# CTRL_MODULE_CORE_PAD register map
Vendor: Texas Instruments
Registers are 32-bit, access per field, reset 0x10F010F unless marked. A register's access mark holds for its fields unless they carry their own. Offsets are as the file gives them; [hi:lo] are bit positions; {n}, {i} and the like mark numbered series; 'fields as' and 'values as' point back to an identical list.

## CTRL_MODULE_CORE_PAD (part 3 of 7)
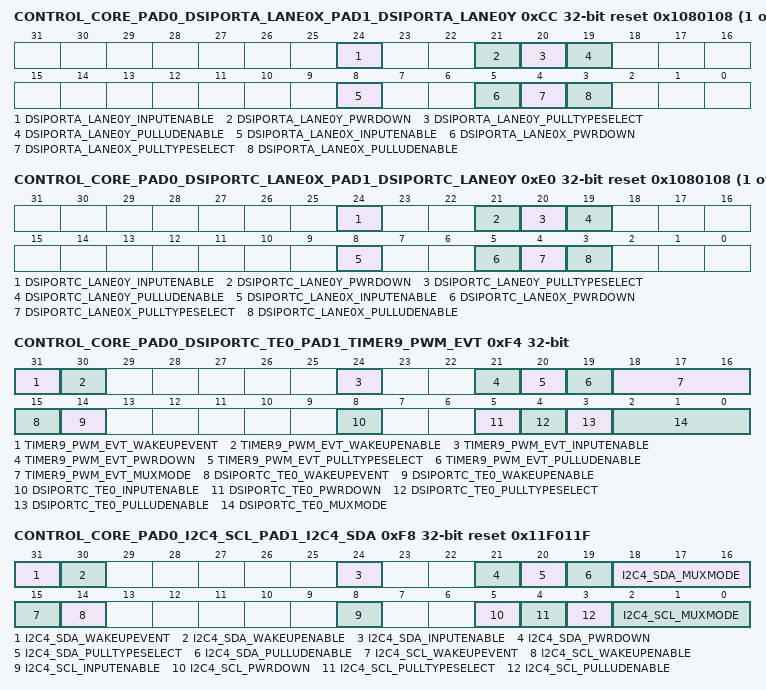
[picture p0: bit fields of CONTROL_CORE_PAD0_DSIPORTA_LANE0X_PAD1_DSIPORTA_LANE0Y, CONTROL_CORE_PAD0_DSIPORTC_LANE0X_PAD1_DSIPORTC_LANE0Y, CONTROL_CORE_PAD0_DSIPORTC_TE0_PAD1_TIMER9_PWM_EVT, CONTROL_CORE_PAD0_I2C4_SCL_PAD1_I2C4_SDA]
{0xCC+4i} CONTROL_CORE_PAD0_DSIPORTA_LANE{i}X_PAD1_DSIPORTA_LANE{i}Y reset 0x1080108 (i=0..4) — Register control for Pads dsiporta_lane{i}x and dsiporta_lane{i}y Access conditions. Read: unrestricted, Write: unrestricted
  [24] DSIPORTA_LANE{i}Y_INPUTENABLE rw — Input enable value for pad dsiporta_lane{i}y
    0=InputBufferDisabled (Input buffer of IO cell is disabled); 1=InputBufferEnabled (Input buffer of IO cell is enabled)
  [21] DSIPORTA_LANE{i}Y_PWRDOWN rw — Power Down setting for pad dsiporta_lane{i}y
    0=PwrDownDisabled (IO cell power is ON); 1=PwrDownEnabled (IO cell power is OFF)
  [20] DSIPORTA_LANE{i}Y_PULLTYPESELECT rw — Pull-Up/Down selection for pad dsiporta_lane{i}y
    0=Pull-Down selected; 1=Pull-Up selected
  [19] DSIPORTA_LANE{i}Y_PULLUDENABLE rw — Pull-Up/Down enable for pad dsiporta_lane{i}y
    0=PullDisabled (Pull-Up/Down disabled); 1=PullEnabled (Pull-Up/Down enabled)
  [8] DSIPORTA_LANE{i}X_INPUTENABLE rw — Input enable value for pad dsiporta_lane{i}x
    values as DSIPORTA_LANE{i}Y_INPUTENABLE
  [5] DSIPORTA_LANE{i}X_PWRDOWN rw — Power Down setting for pad dsiporta_lane{i}x
    values as DSIPORTA_LANE{i}Y_PWRDOWN
  [4] DSIPORTA_LANE{i}X_PULLTYPESELECT rw — Pull-Up/Down selection for pad dsiporta_lane{i}x
    0=Pull-Down selected; 1=Pull-Up selected
  [3] DSIPORTA_LANE{i}X_PULLUDENABLE rw — Pull-Up/Down enable for pad dsiporta_lane{i}x
    values as DSIPORTA_LANE{i}Y_PULLUDENABLE
{0xE0+4i} CONTROL_CORE_PAD0_DSIPORTC_LANE{i}X_PAD1_DSIPORTC_LANE{i}Y reset 0x1080108 (i=0..4) — Register control for Pads dsiportc_lane{i}x and dsiportc_lane{i}y Access conditions. Read: unrestricted, Write: unrestricted
  [24] DSIPORTC_LANE{i}Y_INPUTENABLE rw — Input enable value for pad dsiportc_lane{i}y
    values as CONTROL_CORE_PAD0_DSIPORTA_LANE0X_PAD1_DSIPORTA_LANE0Y.DSIPORTA_LANE{i}Y_INPUTENABLE
  [21] DSIPORTC_LANE{i}Y_PWRDOWN rw — Power Down setting for pad dsiportc_lane{i}y
    values as CONTROL_CORE_PAD0_DSIPORTA_LANE0X_PAD1_DSIPORTA_LANE0Y.DSIPORTA_LANE{i}Y_PWRDOWN
  [20] DSIPORTC_LANE{i}Y_PULLTYPESELECT rw — Pull-Up/Down selection for pad dsiportc_lane{i}y
    0=Pull-Down selected; 1=Pull-Up selected
  [19] DSIPORTC_LANE{i}Y_PULLUDENABLE rw — Pull-Up/Down enable for pad dsiportc_lane{i}y
    values as CONTROL_CORE_PAD0_DSIPORTA_LANE0X_PAD1_DSIPORTA_LANE0Y.DSIPORTA_LANE{i}Y_PULLUDENABLE
  [8] DSIPORTC_LANE{i}X_INPUTENABLE rw — Input enable value for pad dsiportc_lane{i}x
    values as CONTROL_CORE_PAD0_DSIPORTA_LANE0X_PAD1_DSIPORTA_LANE0Y.DSIPORTA_LANE{i}Y_INPUTENABLE
  [5] DSIPORTC_LANE{i}X_PWRDOWN rw — Power Down setting for pad dsiportc_lane{i}x
    values as CONTROL_CORE_PAD0_DSIPORTA_LANE0X_PAD1_DSIPORTA_LANE0Y.DSIPORTA_LANE{i}Y_PWRDOWN
  [4] DSIPORTC_LANE{i}X_PULLTYPESELECT rw — Pull-Up/Down selection for pad dsiportc_lane{i}x
    0=Pull-Down selected; 1=Pull-Up selected
  [3] DSIPORTC_LANE{i}X_PULLUDENABLE rw — Pull-Up/Down enable for pad dsiportc_lane{i}x
    values as CONTROL_CORE_PAD0_DSIPORTA_LANE0X_PAD1_DSIPORTA_LANE0Y.DSIPORTA_LANE{i}Y_PULLUDENABLE
0xF4 CONTROL_CORE_PAD0_DSIPORTC_TE0_PAD1_TIMER9_PWM_EVT — Register control for Pads dsiportc_te0 and timer9_pwm_evt Access conditions. Read: unrestricted, Write: unrestricted
  [31] TIMER9_PWM_EVT_WAKEUPEVENT ro — Pad_x wake-up event status latched in the IO
    1=WakeUp (A wake-up event occurred); 0=No wake-up event occurred
  [30] TIMER9_PWM_EVT_WAKEUPENABLE rw — Input pad wake-up enable
    0=DetectLow (wake-up detection is disabled); 1=DetectLowHigh (wake-up detection is enabled)
  [24] TIMER9_PWM_EVT_INPUTENABLE rw — Input enable value for pad timer9_pwm_evt
    values as CONTROL_CORE_PAD0_DSIPORTA_LANE0X_PAD1_DSIPORTA_LANE0Y.DSIPORTA_LANE{i}Y_INPUTENABLE
  [21] TIMER9_PWM_EVT_PWRDOWN rw — Power Down setting for pad timer9_pwm_evt
    values as CONTROL_CORE_PAD0_DSIPORTA_LANE0X_PAD1_DSIPORTA_LANE0Y.DSIPORTA_LANE{i}Y_PWRDOWN
  [20] TIMER9_PWM_EVT_PULLTYPESELECT rw — Pull-Up/Down selection for pad timer9_pwm_evt
    0=Pull-Down selected; 1=Pull-Up selected
  [19] TIMER9_PWM_EVT_PULLUDENABLE rw — Pull-Up/Down enable for pad timer9_pwm_evt
    values as CONTROL_CORE_PAD0_DSIPORTA_LANE0X_PAD1_DSIPORTA_LANE0Y.DSIPORTA_LANE{i}Y_PULLUDENABLE
  [18:16] TIMER9_PWM_EVT_MUXMODE rw — Functional multiplexing selection for pad timer9_pwm_evt
    0=SEL_TIMER9_PWM_EVT (Select timer9_pwm_evt); 1=SEL_SYNC_SOF_CLK (Select sync_sof_clk); 2=SEL_SYNC_USOF_ITP_CLK (Select sync_usof_itp_clk); 7=SEL_SAFE_MODE_CORE70 (Select safe_mode_core70); 6=SEL_GPIO6_190 (Select gpio6_190)
  [15] DSIPORTC_TE0_WAKEUPEVENT ro — Pad_x wake-up event status latched in the IO
    values as TIMER9_PWM_EVT_WAKEUPEVENT
  [14] DSIPORTC_TE0_WAKEUPENABLE rw — Input pad wake-up enable
    values as TIMER9_PWM_EVT_WAKEUPENABLE
  [8] DSIPORTC_TE0_INPUTENABLE rw — Input enable value for pad dsiportc_te0
    values as CONTROL_CORE_PAD0_DSIPORTA_LANE0X_PAD1_DSIPORTA_LANE0Y.DSIPORTA_LANE{i}Y_INPUTENABLE
  [5] DSIPORTC_TE0_PWRDOWN rw — Power Down setting for pad dsiportc_te0
    values as CONTROL_CORE_PAD0_DSIPORTA_LANE0X_PAD1_DSIPORTA_LANE0Y.DSIPORTA_LANE{i}Y_PWRDOWN
  [4] DSIPORTC_TE0_PULLTYPESELECT rw — Pull-Up/Down selection for pad dsiportc_te0
    0=Pull-Down selected; 1=Pull-Up selected
  [3] DSIPORTC_TE0_PULLUDENABLE rw — Pull-Up/Down enable for pad dsiportc_te0
    values as CONTROL_CORE_PAD0_DSIPORTA_LANE0X_PAD1_DSIPORTA_LANE0Y.DSIPORTA_LANE{i}Y_PULLUDENABLE
  [2:0] DSIPORTC_TE0_MUXMODE rw — Functional multiplexing selection for pad dsiportc_te0
    0=SEL_DSIPORTC_TE0 (Select dsiportc_te0); 7=SEL_SAFE_MODE_CORE71 (Select safe_mode_core71); 6=SEL_GPIO6_191 (Select gpio6_191)
0xF8 CONTROL_CORE_PAD0_I2C4_SCL_PAD1_I2C4_SDA reset 0x11F011F — Register control for Pads i2c4_scl and i2c4_sda Access conditions. Read: unrestricted, Write: unrestricted
  [31] I2C4_SDA_WAKEUPEVENT ro — Pad_x wake-up event status latched in the IO
    values as CONTROL_CORE_PAD0_DSIPORTC_TE0_PAD1_TIMER9_PWM_EVT.TIMER9_PWM_EVT_WAKEUPEVENT
  [30] I2C4_SDA_WAKEUPENABLE rw — Input pad wake-up enable
    values as CONTROL_CORE_PAD0_DSIPORTC_TE0_PAD1_TIMER9_PWM_EVT.TIMER9_PWM_EVT_WAKEUPENABLE
  [24] I2C4_SDA_INPUTENABLE rw — Input enable value for pad i2c4_sda
    values as CONTROL_CORE_PAD0_DSIPORTA_LANE0X_PAD1_DSIPORTA_LANE0Y.DSIPORTA_LANE{i}Y_INPUTENABLE
  [21] I2C4_SDA_PWRDOWN rw — Power Down setting for pad i2c4_sda
    values as CONTROL_CORE_PAD0_DSIPORTA_LANE0X_PAD1_DSIPORTA_LANE0Y.DSIPORTA_LANE{i}Y_PWRDOWN
  [20] I2C4_SDA_PULLTYPESELECT rw — Pull-Up/Down selection for pad i2c4_sda
    0=Pull-Down selected; 1=Pull-Up selected
  [19] I2C4_SDA_PULLUDENABLE rw — Pull-Up/Down enable for pad i2c4_sda
    values as CONTROL_CORE_PAD0_DSIPORTA_LANE0X_PAD1_DSIPORTA_LANE0Y.DSIPORTA_LANE{i}Y_PULLUDENABLE
  [18:16] I2C4_SDA_MUXMODE rw — Functional multiplexing selection for pad i2c4_sda
    0=SEL_I2C4_SDA (Select i2c4_sda); 1=SEL_JTAGTAPEXP_RTCK (Select jtagtapext_rtck); 7=SEL_SAFE_MODE_CORE105 (Select safe_mode_core105); 6=SEL_GPIO7_201 (Select gpio7_201)
  [15] I2C4_SCL_WAKEUPEVENT ro — Pad_x wake-up event status latched in the IO
    values as CONTROL_CORE_PAD0_DSIPORTC_TE0_PAD1_TIMER9_PWM_EVT.TIMER9_PWM_EVT_WAKEUPEVENT
  [14] I2C4_SCL_WAKEUPENABLE rw — Input pad wake-up enable
    values as CONTROL_CORE_PAD0_DSIPORTC_TE0_PAD1_TIMER9_PWM_EVT.TIMER9_PWM_EVT_WAKEUPENABLE
  [8] I2C4_SCL_INPUTENABLE rw — Input enable value for pad i2c4_scl
    values as CONTROL_CORE_PAD0_DSIPORTA_LANE0X_PAD1_DSIPORTA_LANE0Y.DSIPORTA_LANE{i}Y_INPUTENABLE
  [5] I2C4_SCL_PWRDOWN rw — Power Down setting for pad i2c4_scl
    values as CONTROL_CORE_PAD0_DSIPORTA_LANE0X_PAD1_DSIPORTA_LANE0Y.DSIPORTA_LANE{i}Y_PWRDOWN
  [4] I2C4_SCL_PULLTYPESELECT rw — Pull-Up/Down selection for pad i2c4_scl
    0=Pull-Down selected; 1=Pull-Up selected
  [3] I2C4_SCL_PULLUDENABLE rw — Pull-Up/Down enable for pad i2c4_scl
    values as CONTROL_CORE_PAD0_DSIPORTA_LANE0X_PAD1_DSIPORTA_LANE0Y.DSIPORTA_LANE{i}Y_PULLUDENABLE
  [2:0] I2C4_SCL_MUXMODE rw — Functional multiplexing selection for pad i2c4_scl
    0=SEL_I2C4_SCL (Select i2c4_scl); 1=SEL_JTAGTAPEXP_TDI (Select jtagtapext_tdi); 7=SEL_SAFE_MODE_CORE104 (Select safe_mode_core104); 6=SEL_GPIO7_200 (Select gpio7_200)
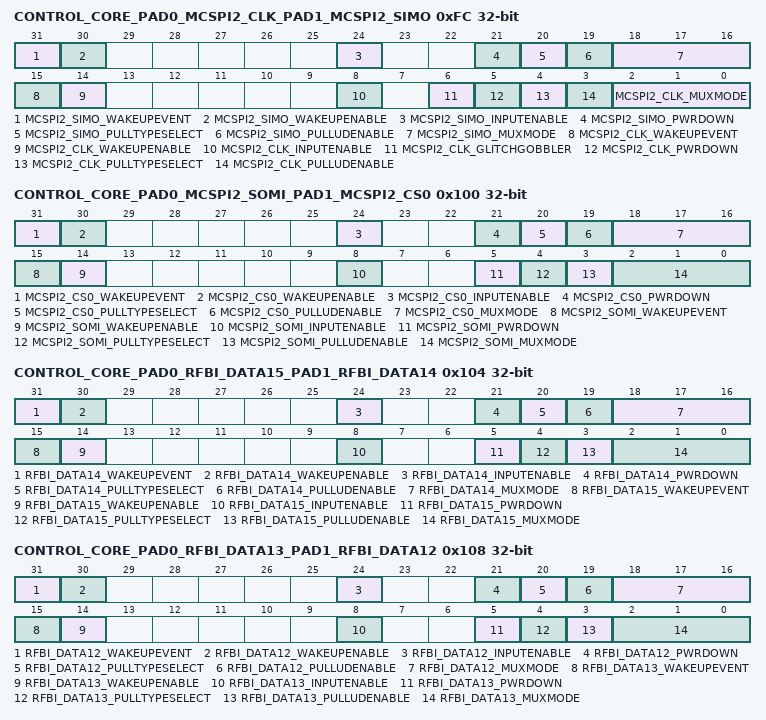
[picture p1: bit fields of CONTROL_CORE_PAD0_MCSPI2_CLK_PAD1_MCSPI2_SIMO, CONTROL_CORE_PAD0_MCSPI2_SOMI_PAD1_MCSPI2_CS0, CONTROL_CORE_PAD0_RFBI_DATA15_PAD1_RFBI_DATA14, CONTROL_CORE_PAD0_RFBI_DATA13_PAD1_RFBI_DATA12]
0xFC CONTROL_CORE_PAD0_MCSPI2_CLK_PAD1_MCSPI2_SIMO — Register control for Pads mcspi2_clk and mcspi2_simo Access conditions. Read: unrestricted, Write: unrestricted
  [31] MCSPI2_SIMO_WAKEUPEVENT ro — Pad_x wake-up event status latched in the IO
    values as CONTROL_CORE_PAD0_DSIPORTC_TE0_PAD1_TIMER9_PWM_EVT.TIMER9_PWM_EVT_WAKEUPEVENT
  [30] MCSPI2_SIMO_WAKEUPENABLE rw — Input pad wake-up enable
    values as CONTROL_CORE_PAD0_DSIPORTC_TE0_PAD1_TIMER9_PWM_EVT.TIMER9_PWM_EVT_WAKEUPENABLE
  [24] MCSPI2_SIMO_INPUTENABLE rw — Input enable value for pad mcspi2_simo
    values as CONTROL_CORE_PAD0_DSIPORTA_LANE0X_PAD1_DSIPORTA_LANE0Y.DSIPORTA_LANE{i}Y_INPUTENABLE
  [21] MCSPI2_SIMO_PWRDOWN rw — Power Down setting for pad mcspi2_simo
    values as CONTROL_CORE_PAD0_DSIPORTA_LANE0X_PAD1_DSIPORTA_LANE0Y.DSIPORTA_LANE{i}Y_PWRDOWN
  [20] MCSPI2_SIMO_PULLTYPESELECT rw — Pull-Up/Down selection for pad mcspi2_simo
    0=Pull-Down selected; 1=Pull-Up selected
  [19] MCSPI2_SIMO_PULLUDENABLE rw — Pull-Up/Down enable for pad mcspi2_simo
    values as CONTROL_CORE_PAD0_DSIPORTA_LANE0X_PAD1_DSIPORTA_LANE0Y.DSIPORTA_LANE{i}Y_PULLUDENABLE
  [18:16] MCSPI2_SIMO_MUXMODE rw — Functional multiplexing selection for pad mcspi2_simo
    0=SEL_MCSPI2_SIMO (Select mcspi2_simo); 1=SEL_JTAGTAPEXT_TMSC (Select jtagtapext_tmsc); 6=SEL_GPIO7_198 (Select gpio7_198); 7=SEL_SAFE_MODE_CORE102 (Select safe_mode_core102); 5=SEL_HW_DBG20 (Select hw_dbg20)
  [15] MCSPI2_CLK_WAKEUPEVENT ro — Pad_x wake-up event status latched in the IO
    values as CONTROL_CORE_PAD0_DSIPORTC_TE0_PAD1_TIMER9_PWM_EVT.TIMER9_PWM_EVT_WAKEUPEVENT
  [14] MCSPI2_CLK_WAKEUPENABLE rw — Input pad wake-up enable
    values as CONTROL_CORE_PAD0_DSIPORTC_TE0_PAD1_TIMER9_PWM_EVT.TIMER9_PWM_EVT_WAKEUPENABLE
  [8] MCSPI2_CLK_INPUTENABLE rw — Input enable value for pad mcspi2_clk
    values as CONTROL_CORE_PAD0_DSIPORTA_LANE0X_PAD1_DSIPORTA_LANE0Y.DSIPORTA_LANE{i}Y_INPUTENABLE
  [6] MCSPI2_CLK_GLITCHGOBBLER rw — Glitch Gobbler setting for pad mcspi2_clk
    0=GlitchGobblerDisabled (IO do not Filter glitch from outside); 1=GlitchGobblerEnabled (IO Filter glitch from outside)
  [5] MCSPI2_CLK_PWRDOWN rw — Power Down setting for pad mcspi2_clk
    values as CONTROL_CORE_PAD0_DSIPORTA_LANE0X_PAD1_DSIPORTA_LANE0Y.DSIPORTA_LANE{i}Y_PWRDOWN
  [4] MCSPI2_CLK_PULLTYPESELECT rw — Pull-Up/Down selection for pad mcspi2_clk
    0=Pull-Down selected; 1=Pull-Up selected
  [3] MCSPI2_CLK_PULLUDENABLE rw — Pull-Up/Down enable for pad mcspi2_clk
    values as CONTROL_CORE_PAD0_DSIPORTA_LANE0X_PAD1_DSIPORTA_LANE0Y.DSIPORTA_LANE{i}Y_PULLUDENABLE
  [2:0] MCSPI2_CLK_MUXMODE rw — Functional multiplexing selection for pad mcspi2_clk
    0=SEL_MCSPI2_CLK (Select mcspi2_clk); 1=SEL_JTAGTAPEXT_TCK (Select jtagtapext_tck); 7=SEL_SAFE_MODE_CORE101 (Select safe_mode_core101); 6=SEL_GPIO7_197 (Select gpio7_197)
0x100 CONTROL_CORE_PAD0_MCSPI2_SOMI_PAD1_MCSPI2_CS0 — Register control for Pads mcspi2_somi and mcspi2_cs0 Access conditions. Read: unrestricted, Write: unrestricted
  [31] MCSPI2_CS0_WAKEUPEVENT ro — Pad_x wake-up event status latched in the IO
    values as CONTROL_CORE_PAD0_DSIPORTC_TE0_PAD1_TIMER9_PWM_EVT.TIMER9_PWM_EVT_WAKEUPEVENT
  [30] MCSPI2_CS0_WAKEUPENABLE rw — Input pad wake-up enable
    values as CONTROL_CORE_PAD0_DSIPORTC_TE0_PAD1_TIMER9_PWM_EVT.TIMER9_PWM_EVT_WAKEUPENABLE
  [24] MCSPI2_CS0_INPUTENABLE rw — Input enable value for pad mcspi2_cs0
    values as CONTROL_CORE_PAD0_DSIPORTA_LANE0X_PAD1_DSIPORTA_LANE0Y.DSIPORTA_LANE{i}Y_INPUTENABLE
  [21] MCSPI2_CS0_PWRDOWN rw — Power Down setting for pad mcspi2_cs0
    values as CONTROL_CORE_PAD0_DSIPORTA_LANE0X_PAD1_DSIPORTA_LANE0Y.DSIPORTA_LANE{i}Y_PWRDOWN
  [20] MCSPI2_CS0_PULLTYPESELECT rw — Pull-Up/Down selection for pad mcspi2_cs0
    0=Pull-Down selected; 1=Pull-Up selected
  [19] MCSPI2_CS0_PULLUDENABLE rw — Pull-Up/Down enable for pad mcspi2_cs0
    values as CONTROL_CORE_PAD0_DSIPORTA_LANE0X_PAD1_DSIPORTA_LANE0Y.DSIPORTA_LANE{i}Y_PULLUDENABLE
  [18:16] MCSPI2_CS0_MUXMODE rw — Functional multiplexing selection for pad mcspi2_cs0
    0=SEL_MCSPI2_CS0 (Select mcspi2_cs0); 1=SEL_JTAGTAPEXT_NTRST (Select jtagtapext_ntrst); 3=SEL_DISPC_FID (Select dispc_fid); 7=SEL_SAFE_MODE_CORE100 (Select safe_mode_core100); 6=SEL_GPIO7_196 (Select gpio7_196)
  [15] MCSPI2_SOMI_WAKEUPEVENT ro — Pad_x wake-up event status latched in the IO
    values as CONTROL_CORE_PAD0_DSIPORTC_TE0_PAD1_TIMER9_PWM_EVT.TIMER9_PWM_EVT_WAKEUPEVENT
  [14] MCSPI2_SOMI_WAKEUPENABLE rw — Input pad wake-up enable
    values as CONTROL_CORE_PAD0_DSIPORTC_TE0_PAD1_TIMER9_PWM_EVT.TIMER9_PWM_EVT_WAKEUPENABLE
  [8] MCSPI2_SOMI_INPUTENABLE rw — Input enable value for pad mcspi2_somi
    values as CONTROL_CORE_PAD0_DSIPORTA_LANE0X_PAD1_DSIPORTA_LANE0Y.DSIPORTA_LANE{i}Y_INPUTENABLE
  [5] MCSPI2_SOMI_PWRDOWN rw — Power Down setting for pad mcspi2_somi
    values as CONTROL_CORE_PAD0_DSIPORTA_LANE0X_PAD1_DSIPORTA_LANE0Y.DSIPORTA_LANE{i}Y_PWRDOWN
  [4] MCSPI2_SOMI_PULLTYPESELECT rw — Pull-Up/Down selection for pad mcspi2_somi
    0=Pull-Down selected; 1=Pull-Up selected
  [3] MCSPI2_SOMI_PULLUDENABLE rw — Pull-Up/Down enable for pad mcspi2_somi
    values as CONTROL_CORE_PAD0_DSIPORTA_LANE0X_PAD1_DSIPORTA_LANE0Y.DSIPORTA_LANE{i}Y_PULLUDENABLE
  [2:0] MCSPI2_SOMI_MUXMODE rw — Functional multiplexing selection for pad mcspi2_somi
    0=SEL_MCSPI2_SOMI (Select mcspi2_somi); 1=SEL_JTAGTAPEXT_TDO (Select jtagtapext_tdo); 6=SEL_GPIO7_199 (Select gpio7_199); 7=SEL_SAFE_MODE_CORE103 (Select safe_mode_core103); 5=SEL_HW_DBG21 (Select hw_dbg21)
0x104 CONTROL_CORE_PAD0_RFBI_DATA15_PAD1_RFBI_DATA14 — Register control for Pads rfbi_data15 and rfbi_data14 Access conditions. Read: unrestricted, Write: unrestricted
  [31] RFBI_DATA14_WAKEUPEVENT ro — Pad_x wake-up event status latched in the IO
    values as CONTROL_CORE_PAD0_DSIPORTC_TE0_PAD1_TIMER9_PWM_EVT.TIMER9_PWM_EVT_WAKEUPEVENT
  [30] RFBI_DATA14_WAKEUPENABLE rw — Input pad wake-up enable
    values as CONTROL_CORE_PAD0_DSIPORTC_TE0_PAD1_TIMER9_PWM_EVT.TIMER9_PWM_EVT_WAKEUPENABLE
  [24] RFBI_DATA14_INPUTENABLE rw — Input enable value for pad rfbi_data14
    values as CONTROL_CORE_PAD0_DSIPORTA_LANE0X_PAD1_DSIPORTA_LANE0Y.DSIPORTA_LANE{i}Y_INPUTENABLE
  [21] RFBI_DATA14_PWRDOWN rw — Power Down setting for pad rfbi_data14
    values as CONTROL_CORE_PAD0_DSIPORTA_LANE0X_PAD1_DSIPORTA_LANE0Y.DSIPORTA_LANE{i}Y_PWRDOWN
  [20] RFBI_DATA14_PULLTYPESELECT rw — Pull-Up/Down selection for pad rfbi_data14
    0=Pull-Down selected; 1=Pull-Up selected
  [19] RFBI_DATA14_PULLUDENABLE rw — Pull-Up/Down enable for pad rfbi_data14
    values as CONTROL_CORE_PAD0_DSIPORTA_LANE0X_PAD1_DSIPORTA_LANE0Y.DSIPORTA_LANE{i}Y_PULLUDENABLE
  [18:16] RFBI_DATA14_MUXMODE rw — Functional multiplexing selection for pad rfbi_data14
    6=SEL_GPIO6_180 (Select gpio6_180); 7=SEL_SAFE_MODE_CORE82 (Select safe_mode_core82); 0=SEL_RFBI_DATA14 (Select rfbi_data14); 4=SEL_KBD_COL7 (Select kbd_col7); 5=SEL_DRM_EMU18 (Select drm_emu18); 3=SEL_DISPC_DATA14 (Select dispc_data14)
  [15] RFBI_DATA15_WAKEUPEVENT ro — Pad_x wake-up event status latched in the IO
    values as CONTROL_CORE_PAD0_DSIPORTC_TE0_PAD1_TIMER9_PWM_EVT.TIMER9_PWM_EVT_WAKEUPEVENT
  [14] RFBI_DATA15_WAKEUPENABLE rw — Input pad wake-up enable
    values as CONTROL_CORE_PAD0_DSIPORTC_TE0_PAD1_TIMER9_PWM_EVT.TIMER9_PWM_EVT_WAKEUPENABLE
  [8] RFBI_DATA15_INPUTENABLE rw — Input enable value for pad rfbi_data15
    values as CONTROL_CORE_PAD0_DSIPORTA_LANE0X_PAD1_DSIPORTA_LANE0Y.DSIPORTA_LANE{i}Y_INPUTENABLE
  [5] RFBI_DATA15_PWRDOWN rw — Power Down setting for pad rfbi_data15
    values as CONTROL_CORE_PAD0_DSIPORTA_LANE0X_PAD1_DSIPORTA_LANE0Y.DSIPORTA_LANE{i}Y_PWRDOWN
  [4] RFBI_DATA15_PULLTYPESELECT rw — Pull-Up/Down selection for pad rfbi_data15
    0=Pull-Down selected; 1=Pull-Up selected
  [3] RFBI_DATA15_PULLUDENABLE rw — Pull-Up/Down enable for pad rfbi_data15
    values as CONTROL_CORE_PAD0_DSIPORTA_LANE0X_PAD1_DSIPORTA_LANE0Y.DSIPORTA_LANE{i}Y_PULLUDENABLE
  [2:0] RFBI_DATA15_MUXMODE rw — Functional multiplexing selection for pad rfbi_data15
    6=SEL_GPIO6_181 (Select gpio6_181); 1=SEL_MCSPI2_CS1 (Select mcspi2_cs1); 7=SEL_SAFE_MODE_CORE83 (Select safe_mode_core83); 0=SEL_RFBI_DATA15 (Select rfbi_data15); 4=SEL_KBD_COL6 (Select kbd_col6); 5=SEL_DRM_EMU19 (Select drm_emu19); 3=SEL_DISPC_DATA15 (Select dispc_data15)
0x108 CONTROL_CORE_PAD0_RFBI_DATA13_PAD1_RFBI_DATA12 — Register control for Pads rfbi_data13 and rfbi_data12 Access conditions. Read: unrestricted, Write: unrestricted
  [31] RFBI_DATA12_WAKEUPEVENT ro — Pad_x wake-up event status latched in the IO
    values as CONTROL_CORE_PAD0_DSIPORTC_TE0_PAD1_TIMER9_PWM_EVT.TIMER9_PWM_EVT_WAKEUPEVENT
  [30] RFBI_DATA12_WAKEUPENABLE rw — Input pad wake-up enable
    values as CONTROL_CORE_PAD0_DSIPORTC_TE0_PAD1_TIMER9_PWM_EVT.TIMER9_PWM_EVT_WAKEUPENABLE
  [24] RFBI_DATA12_INPUTENABLE rw — Input enable value for pad rfbi_data12
    values as CONTROL_CORE_PAD0_DSIPORTA_LANE0X_PAD1_DSIPORTA_LANE0Y.DSIPORTA_LANE{i}Y_INPUTENABLE
  [21] RFBI_DATA12_PWRDOWN rw — Power Down setting for pad rfbi_data12
    values as CONTROL_CORE_PAD0_DSIPORTA_LANE0X_PAD1_DSIPORTA_LANE0Y.DSIPORTA_LANE{i}Y_PWRDOWN
  [20] RFBI_DATA12_PULLTYPESELECT rw — Pull-Up/Down selection for pad rfbi_data12
    0=Pull-Down selected; 1=Pull-Up selected
  [19] RFBI_DATA12_PULLUDENABLE rw — Pull-Up/Down enable for pad rfbi_data12
    values as CONTROL_CORE_PAD0_DSIPORTA_LANE0X_PAD1_DSIPORTA_LANE0Y.DSIPORTA_LANE{i}Y_PULLUDENABLE
  [18:16] RFBI_DATA12_MUXMODE rw — Functional multiplexing selection for pad rfbi_data12
    6=SEL_GPIO6_178 (Select gpio6_178); 7=SEL_SAFE_MODE_CORE80 (Select safe_mode_core80); 0=SEL_RFBI_DATA12 (Select rfbi_data12); 4=SEL_KBD_ROW6 (Select kbd_row6); 5=SEL_DRM_EMU16 (Select drm_emu16); 3=SEL_DISPC_DATA12 (Select dispc_data12)
  [15] RFBI_DATA13_WAKEUPEVENT ro — Pad_x wake-up event status latched in the IO
    values as CONTROL_CORE_PAD0_DSIPORTC_TE0_PAD1_TIMER9_PWM_EVT.TIMER9_PWM_EVT_WAKEUPEVENT
  [14] RFBI_DATA13_WAKEUPENABLE rw — Input pad wake-up enable
    values as CONTROL_CORE_PAD0_DSIPORTC_TE0_PAD1_TIMER9_PWM_EVT.TIMER9_PWM_EVT_WAKEUPENABLE
  [8] RFBI_DATA13_INPUTENABLE rw — Input enable value for pad rfbi_data13
    values as CONTROL_CORE_PAD0_DSIPORTA_LANE0X_PAD1_DSIPORTA_LANE0Y.DSIPORTA_LANE{i}Y_INPUTENABLE
  [5] RFBI_DATA13_PWRDOWN rw — Power Down setting for pad rfbi_data13
    values as CONTROL_CORE_PAD0_DSIPORTA_LANE0X_PAD1_DSIPORTA_LANE0Y.DSIPORTA_LANE{i}Y_PWRDOWN
  [4] RFBI_DATA13_PULLTYPESELECT rw — Pull-Up/Down selection for pad rfbi_data13
    0=Pull-Down selected; 1=Pull-Up selected
  [3] RFBI_DATA13_PULLUDENABLE rw — Pull-Up/Down enable for pad rfbi_data13
    values as CONTROL_CORE_PAD0_DSIPORTA_LANE0X_PAD1_DSIPORTA_LANE0Y.DSIPORTA_LANE{i}Y_PULLUDENABLE
  [2:0] RFBI_DATA13_MUXMODE rw — Functional multiplexing selection for pad rfbi_data13
    6=SEL_GPIO6_179 (Select gpio6_179); 7=SEL_SAFE_MODE_CORE81 (Select safe_mode_core81); 0=SEL_RFBI_DATA13 (Select rfbi_data13); 4=SEL_KBD_COL8 (Select kbd_col8); 5=SEL_DRM_EMU17 (Select drm_emu17); 3=SEL_DISPC_DATA13 (Select dispc_data13)
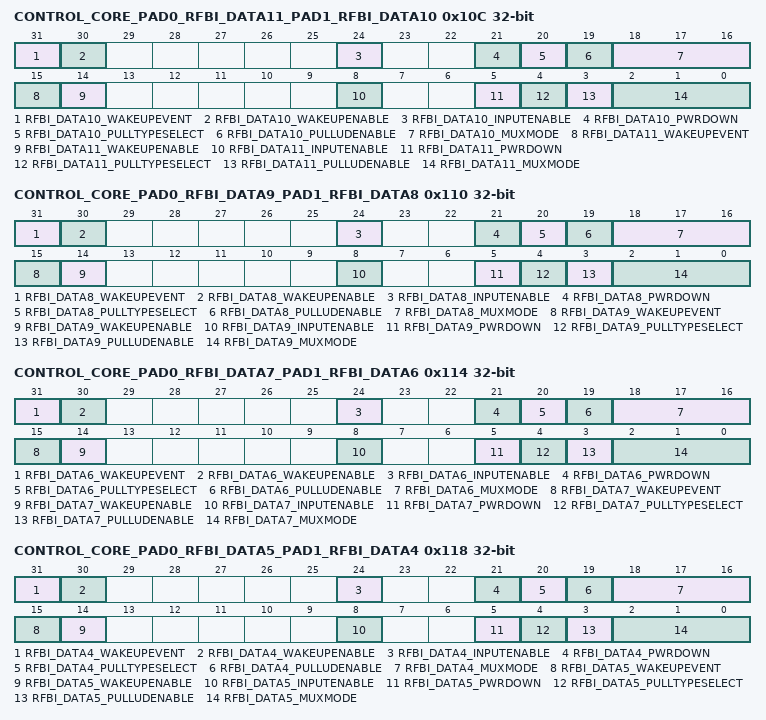
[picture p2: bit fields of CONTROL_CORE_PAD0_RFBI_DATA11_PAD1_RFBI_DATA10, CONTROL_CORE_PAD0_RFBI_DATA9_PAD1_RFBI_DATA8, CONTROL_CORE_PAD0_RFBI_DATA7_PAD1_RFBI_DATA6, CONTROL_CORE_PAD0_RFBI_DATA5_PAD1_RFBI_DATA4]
0x10C CONTROL_CORE_PAD0_RFBI_DATA11_PAD1_RFBI_DATA10 — Register control for Pads rfbi_data11 and rfbi_data10 Access conditions. Read: unrestricted, Write: unrestricted
  [31] RFBI_DATA10_WAKEUPEVENT ro — Pad_x wake-up event status latched in the IO
    values as CONTROL_CORE_PAD0_DSIPORTC_TE0_PAD1_TIMER9_PWM_EVT.TIMER9_PWM_EVT_WAKEUPEVENT
  [30] RFBI_DATA10_WAKEUPENABLE rw — Input pad wake-up enable
    values as CONTROL_CORE_PAD0_DSIPORTC_TE0_PAD1_TIMER9_PWM_EVT.TIMER9_PWM_EVT_WAKEUPENABLE
  [24] RFBI_DATA10_INPUTENABLE rw — Input enable value for pad rfbi_data10
    values as CONTROL_CORE_PAD0_DSIPORTA_LANE0X_PAD1_DSIPORTA_LANE0Y.DSIPORTA_LANE{i}Y_INPUTENABLE
  [21] RFBI_DATA10_PWRDOWN rw — Power Down setting for pad rfbi_data10
    values as CONTROL_CORE_PAD0_DSIPORTA_LANE0X_PAD1_DSIPORTA_LANE0Y.DSIPORTA_LANE{i}Y_PWRDOWN
  [20] RFBI_DATA10_PULLTYPESELECT rw — Pull-Up/Down selection for pad rfbi_data10
    0=Pull-Down selected; 1=Pull-Up selected
  [19] RFBI_DATA10_PULLUDENABLE rw — Pull-Up/Down enable for pad rfbi_data10
    values as CONTROL_CORE_PAD0_DSIPORTA_LANE0X_PAD1_DSIPORTA_LANE0Y.DSIPORTA_LANE{i}Y_PULLUDENABLE
  [18:16] RFBI_DATA10_MUXMODE rw — Functional multiplexing selection for pad rfbi_data10
    6=SEL_GPIO6_176 (Select gpio6_176); 7=SEL_SAFE_MODE_CORE78 (Select safe_mode_core78); 0=SEL_RFBI_DATA10 (Select rfbi_data10); 4=SEL_KBD_ROW8 (Select kbd_row8); 5=SEL_DRM_EMU14 (Select drm_emu14); 3=SEL_DISPC_DATA10 (Select dispc_data10)
  [15] RFBI_DATA11_WAKEUPEVENT ro — Pad_x wake-up event status latched in the IO
    values as CONTROL_CORE_PAD0_DSIPORTC_TE0_PAD1_TIMER9_PWM_EVT.TIMER9_PWM_EVT_WAKEUPEVENT
  [14] RFBI_DATA11_WAKEUPENABLE rw — Input pad wake-up enable
    values as CONTROL_CORE_PAD0_DSIPORTC_TE0_PAD1_TIMER9_PWM_EVT.TIMER9_PWM_EVT_WAKEUPENABLE
  [8] RFBI_DATA11_INPUTENABLE rw — Input enable value for pad rfbi_data11
    values as CONTROL_CORE_PAD0_DSIPORTA_LANE0X_PAD1_DSIPORTA_LANE0Y.DSIPORTA_LANE{i}Y_INPUTENABLE
  [5] RFBI_DATA11_PWRDOWN rw — Power Down setting for pad rfbi_data11
    values as CONTROL_CORE_PAD0_DSIPORTA_LANE0X_PAD1_DSIPORTA_LANE0Y.DSIPORTA_LANE{i}Y_PWRDOWN
  [4] RFBI_DATA11_PULLTYPESELECT rw — Pull-Up/Down selection for pad rfbi_data11
    0=Pull-Down selected; 1=Pull-Up selected
  [3] RFBI_DATA11_PULLUDENABLE rw — Pull-Up/Down enable for pad rfbi_data11
    values as CONTROL_CORE_PAD0_DSIPORTA_LANE0X_PAD1_DSIPORTA_LANE0Y.DSIPORTA_LANE{i}Y_PULLUDENABLE
  [2:0] RFBI_DATA11_MUXMODE rw — Functional multiplexing selection for pad rfbi_data11
    6=SEL_GPIO6_177 (Select gpio6_177); 7=SEL_SAFE_MODE_CORE79 (Select safe_mode_core79); 0=SEL_RFBI_DATA11 (Select rfbi_data11); 4=SEL_KBD_ROW7 (Select kbd_row7); 5=SEL_DRM_EMU15 (Select drm_emu15); 3=SEL_DISPC_DATA11 (Select dispc_data11)
0x110 CONTROL_CORE_PAD0_RFBI_DATA9_PAD1_RFBI_DATA8 — Register control for Pads rfbi_data9 and rfbi_data8 Access conditions. Read: unrestricted, Write: unrestricted
  [31] RFBI_DATA8_WAKEUPEVENT ro — Pad_x wake-up event status latched in the IO
    values as CONTROL_CORE_PAD0_DSIPORTC_TE0_PAD1_TIMER9_PWM_EVT.TIMER9_PWM_EVT_WAKEUPEVENT
  [30] RFBI_DATA8_WAKEUPENABLE rw — Input pad wake-up enable
    values as CONTROL_CORE_PAD0_DSIPORTC_TE0_PAD1_TIMER9_PWM_EVT.TIMER9_PWM_EVT_WAKEUPENABLE
  [24] RFBI_DATA8_INPUTENABLE rw — Input enable value for pad rfbi_data8
    values as CONTROL_CORE_PAD0_DSIPORTA_LANE0X_PAD1_DSIPORTA_LANE0Y.DSIPORTA_LANE{i}Y_INPUTENABLE
  [21] RFBI_DATA8_PWRDOWN rw — Power Down setting for pad rfbi_data8
    values as CONTROL_CORE_PAD0_DSIPORTA_LANE0X_PAD1_DSIPORTA_LANE0Y.DSIPORTA_LANE{i}Y_PWRDOWN
  [20] RFBI_DATA8_PULLTYPESELECT rw — Pull-Up/Down selection for pad rfbi_data8
    0=Pull-Down selected; 1=Pull-Up selected
  [19] RFBI_DATA8_PULLUDENABLE rw — Pull-Up/Down enable for pad rfbi_data8
    values as CONTROL_CORE_PAD0_DSIPORTA_LANE0X_PAD1_DSIPORTA_LANE0Y.DSIPORTA_LANE{i}Y_PULLUDENABLE
  [18:16] RFBI_DATA8_MUXMODE rw — Functional multiplexing selection for pad rfbi_data8
    6=SEL_GPIO6_174 (Select gpio6_174); 7=SEL_SAFE_MODE_CORE76 (Select safe_mode_core76); 0=SEL_RFBI_DATA8 (Select rfbi_data8); 4=SEL_KBD_COL3 (Select kbd_col3); 5=SEL_DRM_EMU12 (Select drm_emu12); 3=SEL_DISPC_DATA8 (Select dispc_data8)
  [15] RFBI_DATA9_WAKEUPEVENT ro — Pad_x wake-up event status latched in the IO
    values as CONTROL_CORE_PAD0_DSIPORTC_TE0_PAD1_TIMER9_PWM_EVT.TIMER9_PWM_EVT_WAKEUPEVENT
  [14] RFBI_DATA9_WAKEUPENABLE rw — Input pad wake-up enable
    values as CONTROL_CORE_PAD0_DSIPORTC_TE0_PAD1_TIMER9_PWM_EVT.TIMER9_PWM_EVT_WAKEUPENABLE
  [8] RFBI_DATA9_INPUTENABLE rw — Input enable value for pad rfbi_data9
    values as CONTROL_CORE_PAD0_DSIPORTA_LANE0X_PAD1_DSIPORTA_LANE0Y.DSIPORTA_LANE{i}Y_INPUTENABLE
  [5] RFBI_DATA9_PWRDOWN rw — Power Down setting for pad rfbi_data9
    values as CONTROL_CORE_PAD0_DSIPORTA_LANE0X_PAD1_DSIPORTA_LANE0Y.DSIPORTA_LANE{i}Y_PWRDOWN
  [4] RFBI_DATA9_PULLTYPESELECT rw — Pull-Up/Down selection for pad rfbi_data9
    0=Pull-Down selected; 1=Pull-Up selected
  [3] RFBI_DATA9_PULLUDENABLE rw — Pull-Up/Down enable for pad rfbi_data9
    values as CONTROL_CORE_PAD0_DSIPORTA_LANE0X_PAD1_DSIPORTA_LANE0Y.DSIPORTA_LANE{i}Y_PULLUDENABLE
  [2:0] RFBI_DATA9_MUXMODE rw — Functional multiplexing selection for pad rfbi_data9
    6=SEL_GPIO6_175 (Select gpio6_175); 7=SEL_SAFE_MODE_CORE77 (Select safe_mode_core77); 0=SEL_RFBI_DATA9 (Select rfbi_data9); 4=SEL_KBD_ROW3 (Select kbd_row3); 5=SEL_DRM_EMU13 (Select drm_emu13); 3=SEL_DISPC_DATA9 (Select dispc_data9)
0x114 CONTROL_CORE_PAD0_RFBI_DATA7_PAD1_RFBI_DATA6 — Register control for Pads rfbi_data7 and rfbi_data6 Access conditions. Read: unrestricted, Write: unrestricted
  [31] RFBI_DATA6_WAKEUPEVENT ro — Pad_x wake-up event status latched in the IO
    values as CONTROL_CORE_PAD0_DSIPORTC_TE0_PAD1_TIMER9_PWM_EVT.TIMER9_PWM_EVT_WAKEUPEVENT
  [30] RFBI_DATA6_WAKEUPENABLE rw — Input pad wake-up enable
    values as CONTROL_CORE_PAD0_DSIPORTC_TE0_PAD1_TIMER9_PWM_EVT.TIMER9_PWM_EVT_WAKEUPENABLE
  [24] RFBI_DATA6_INPUTENABLE rw — Input enable value for pad rfbi_data6
    values as CONTROL_CORE_PAD0_DSIPORTA_LANE0X_PAD1_DSIPORTA_LANE0Y.DSIPORTA_LANE{i}Y_INPUTENABLE
  [21] RFBI_DATA6_PWRDOWN rw — Power Down setting for pad rfbi_data6
    values as CONTROL_CORE_PAD0_DSIPORTA_LANE0X_PAD1_DSIPORTA_LANE0Y.DSIPORTA_LANE{i}Y_PWRDOWN
  [20] RFBI_DATA6_PULLTYPESELECT rw — Pull-Up/Down selection for pad rfbi_data6
    0=Pull-Down selected; 1=Pull-Up selected
  [19] RFBI_DATA6_PULLUDENABLE rw — Pull-Up/Down enable for pad rfbi_data6
    values as CONTROL_CORE_PAD0_DSIPORTA_LANE0X_PAD1_DSIPORTA_LANE0Y.DSIPORTA_LANE{i}Y_PULLUDENABLE
  [18:16] RFBI_DATA6_MUXMODE rw — Functional multiplexing selection for pad rfbi_data6
    0=SEL_RFBI_DATA6 (Select rfbi_data6); 6=SEL_GPIO6_172 (Select gpio6_172); 3=SEL_DISPC_DATA6 (Select dispc_data6); 4=SEL_JTAGTAPEXT_TDO (Select jtagtapext_tdo); 7=SEL_SAFE_MODE_CORE96 (Select safe_mode_core96); 5=SEL_DRM_EMU10 (Select drm_emu10)
  [15] RFBI_DATA7_WAKEUPEVENT ro — Pad_x wake-up event status latched in the IO
    values as CONTROL_CORE_PAD0_DSIPORTC_TE0_PAD1_TIMER9_PWM_EVT.TIMER9_PWM_EVT_WAKEUPEVENT
  [14] RFBI_DATA7_WAKEUPENABLE rw — Input pad wake-up enable
    values as CONTROL_CORE_PAD0_DSIPORTC_TE0_PAD1_TIMER9_PWM_EVT.TIMER9_PWM_EVT_WAKEUPENABLE
  [8] RFBI_DATA7_INPUTENABLE rw — Input enable value for pad rfbi_data7
    values as CONTROL_CORE_PAD0_DSIPORTA_LANE0X_PAD1_DSIPORTA_LANE0Y.DSIPORTA_LANE{i}Y_INPUTENABLE
  [5] RFBI_DATA7_PWRDOWN rw — Power Down setting for pad rfbi_data7
    values as CONTROL_CORE_PAD0_DSIPORTA_LANE0X_PAD1_DSIPORTA_LANE0Y.DSIPORTA_LANE{i}Y_PWRDOWN
  [4] RFBI_DATA7_PULLTYPESELECT rw — Pull-Up/Down selection for pad rfbi_data7
    0=Pull-Down selected; 1=Pull-Up selected
  [3] RFBI_DATA7_PULLUDENABLE rw — Pull-Up/Down enable for pad rfbi_data7
    values as CONTROL_CORE_PAD0_DSIPORTA_LANE0X_PAD1_DSIPORTA_LANE0Y.DSIPORTA_LANE{i}Y_PULLUDENABLE
  [2:0] RFBI_DATA7_MUXMODE rw — Functional multiplexing selection for pad rfbi_data7
    0=SEL_RFBI_DATA7 (Select rfbi_data7); 6=SEL_GPIO6_173 (Select gpio6_173); 3=SEL_DISPC_DATA7 (Select dispc_data7); 4=SEL_JTAGTAPEXT_TDI (Select jtagtapext_tdi); 7=SEL_SAFE_MODE_CORE97 (Select safe_mode_core97); 5=SEL_DRM_EMU11 (Select drm_emu11)
0x118 CONTROL_CORE_PAD0_RFBI_DATA5_PAD1_RFBI_DATA4 — Register control for Pads rfbi_data5 and rfbi_data4 Access conditions. Read: unrestricted, Write: unrestricted
  [31] RFBI_DATA4_WAKEUPEVENT ro — Pad_x wake-up event status latched in the IO
    values as CONTROL_CORE_PAD0_DSIPORTC_TE0_PAD1_TIMER9_PWM_EVT.TIMER9_PWM_EVT_WAKEUPEVENT
  [30] RFBI_DATA4_WAKEUPENABLE rw — Input pad wake-up enable
    values as CONTROL_CORE_PAD0_DSIPORTC_TE0_PAD1_TIMER9_PWM_EVT.TIMER9_PWM_EVT_WAKEUPENABLE
  [24] RFBI_DATA4_INPUTENABLE rw — Input enable value for pad rfbi_data4
    values as CONTROL_CORE_PAD0_DSIPORTA_LANE0X_PAD1_DSIPORTA_LANE0Y.DSIPORTA_LANE{i}Y_INPUTENABLE
  [21] RFBI_DATA4_PWRDOWN rw — Power Down setting for pad rfbi_data4
    values as CONTROL_CORE_PAD0_DSIPORTA_LANE0X_PAD1_DSIPORTA_LANE0Y.DSIPORTA_LANE{i}Y_PWRDOWN
  [20] RFBI_DATA4_PULLTYPESELECT rw — Pull-Up/Down selection for pad rfbi_data4
    0=Pull-Down selected; 1=Pull-Up selected
  [19] RFBI_DATA4_PULLUDENABLE rw — Pull-Up/Down enable for pad rfbi_data4
    values as CONTROL_CORE_PAD0_DSIPORTA_LANE0X_PAD1_DSIPORTA_LANE0Y.DSIPORTA_LANE{i}Y_PULLUDENABLE
  [18:16] RFBI_DATA4_MUXMODE rw — Functional multiplexing selection for pad rfbi_data4
    0=SEL_RFBI_DATA4 (Select rfbi_data4); 6=SEL_GPIO6_170 (Select gpio6_170); 3=SEL_DISPC_DATA4 (Select dispc_data4); 4=SEC_JTAGTAPEXT_TCK (Select jtagtapext_tck); 7=SEL_SAFE_MODE_CORE94 (Select safe_mode_core94); 5=SEL_DRM_EMU8 (Select drm_emu8)
  [15] RFBI_DATA5_WAKEUPEVENT ro — Pad_x wake-up event status latched in the IO
    values as CONTROL_CORE_PAD0_DSIPORTC_TE0_PAD1_TIMER9_PWM_EVT.TIMER9_PWM_EVT_WAKEUPEVENT
  [14] RFBI_DATA5_WAKEUPENABLE rw — Input pad wake-up enable
    values as CONTROL_CORE_PAD0_DSIPORTC_TE0_PAD1_TIMER9_PWM_EVT.TIMER9_PWM_EVT_WAKEUPENABLE
  [8] RFBI_DATA5_INPUTENABLE rw — Input enable value for pad rfbi_data5
    values as CONTROL_CORE_PAD0_DSIPORTA_LANE0X_PAD1_DSIPORTA_LANE0Y.DSIPORTA_LANE{i}Y_INPUTENABLE
  [5] RFBI_DATA5_PWRDOWN rw — Power Down setting for pad rfbi_data5
    values as CONTROL_CORE_PAD0_DSIPORTA_LANE0X_PAD1_DSIPORTA_LANE0Y.DSIPORTA_LANE{i}Y_PWRDOWN
  [4] RFBI_DATA5_PULLTYPESELECT rw — Pull-Up/Down selection for pad rfbi_data5
    0=Pull-Down selected; 1=Pull-Up selected
  [3] RFBI_DATA5_PULLUDENABLE rw — Pull-Up/Down enable for pad rfbi_data5
    values as CONTROL_CORE_PAD0_DSIPORTA_LANE0X_PAD1_DSIPORTA_LANE0Y.DSIPORTA_LANE{i}Y_PULLUDENABLE
  [2:0] RFBI_DATA5_MUXMODE rw — Functional multiplexing selection for pad rfbi_data5
    0=SEL_RFBI_DATA5 (Select rfbi_data5); 6=SEL_GPIO6_171 (Select gpio6_171); 3=SEL_DISPC_DATA5 (Select dispc_data5); 4=SEL_JTAGTAPEXT_TMSC (Select jtagtapext_tmsc); 7=SEL_SAFE_MODE_CORE95 (Select safe_mode_core95); 5=SEL_DRM_EMU9 (Select drm_emu9)
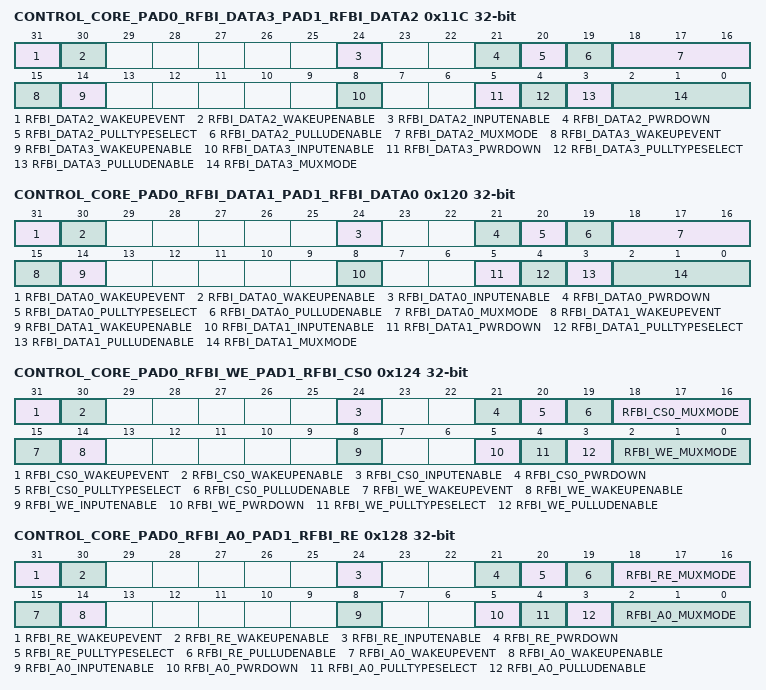
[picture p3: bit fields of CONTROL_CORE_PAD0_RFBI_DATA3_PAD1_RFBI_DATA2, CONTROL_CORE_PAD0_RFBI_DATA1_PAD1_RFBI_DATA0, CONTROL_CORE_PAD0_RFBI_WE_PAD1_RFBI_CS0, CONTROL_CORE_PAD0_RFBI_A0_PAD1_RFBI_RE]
0x11C CONTROL_CORE_PAD0_RFBI_DATA3_PAD1_RFBI_DATA2 — Register control for Pads rfbi_data3 and rfbi_data2 Access conditions. Read: unrestricted, Write: unrestricted
  [31] RFBI_DATA2_WAKEUPEVENT ro — Pad_x wake-up event status latched in the IO
    values as CONTROL_CORE_PAD0_DSIPORTC_TE0_PAD1_TIMER9_PWM_EVT.TIMER9_PWM_EVT_WAKEUPEVENT
  [30] RFBI_DATA2_WAKEUPENABLE rw — Input pad wake-up enable
    values as CONTROL_CORE_PAD0_DSIPORTC_TE0_PAD1_TIMER9_PWM_EVT.TIMER9_PWM_EVT_WAKEUPENABLE
  [24] RFBI_DATA2_INPUTENABLE rw — Input enable value for pad rfbi_data2
    values as CONTROL_CORE_PAD0_DSIPORTA_LANE0X_PAD1_DSIPORTA_LANE0Y.DSIPORTA_LANE{i}Y_INPUTENABLE
  [21] RFBI_DATA2_PWRDOWN rw — Power Down setting for pad rfbi_data2
    values as CONTROL_CORE_PAD0_DSIPORTA_LANE0X_PAD1_DSIPORTA_LANE0Y.DSIPORTA_LANE{i}Y_PWRDOWN
  [20] RFBI_DATA2_PULLTYPESELECT rw — Pull-Up/Down selection for pad rfbi_data2
    0=Pull-Down selected; 1=Pull-Up selected
  [19] RFBI_DATA2_PULLUDENABLE rw — Pull-Up/Down enable for pad rfbi_data2
    values as CONTROL_CORE_PAD0_DSIPORTA_LANE0X_PAD1_DSIPORTA_LANE0Y.DSIPORTA_LANE{i}Y_PULLUDENABLE
  [18:16] RFBI_DATA2_MUXMODE rw — Functional multiplexing selection for pad rfbi_data2
    6=SEL_GPIO6_168 (Select gpio6_168); 7=SEL_SAFE_MODE_CORE92 (Select safe_mode_core92); 0=SEL_RFBI_DATA2 (Select rfbi_data2); 4=SEL_UART3_TX_IRTX (Select uart3_tx_irtx); 5=SEL_DRM_EMU6 (Select drm_emu6); 3=SEL_DISPC_DATA2 (Select dispc_data2)
  [15] RFBI_DATA3_WAKEUPEVENT ro — Pad_x wake-up event status latched in the IO
    values as CONTROL_CORE_PAD0_DSIPORTC_TE0_PAD1_TIMER9_PWM_EVT.TIMER9_PWM_EVT_WAKEUPEVENT
  [14] RFBI_DATA3_WAKEUPENABLE rw — Input pad wake-up enable
    values as CONTROL_CORE_PAD0_DSIPORTC_TE0_PAD1_TIMER9_PWM_EVT.TIMER9_PWM_EVT_WAKEUPENABLE
  [8] RFBI_DATA3_INPUTENABLE rw — Input enable value for pad rfbi_data3
    values as CONTROL_CORE_PAD0_DSIPORTA_LANE0X_PAD1_DSIPORTA_LANE0Y.DSIPORTA_LANE{i}Y_INPUTENABLE
  [5] RFBI_DATA3_PWRDOWN rw — Power Down setting for pad rfbi_data3
    values as CONTROL_CORE_PAD0_DSIPORTA_LANE0X_PAD1_DSIPORTA_LANE0Y.DSIPORTA_LANE{i}Y_PWRDOWN
  [4] RFBI_DATA3_PULLTYPESELECT rw — Pull-Up/Down selection for pad rfbi_data3
    0=Pull-Down selected; 1=Pull-Up selected
  [3] RFBI_DATA3_PULLUDENABLE rw — Pull-Up/Down enable for pad rfbi_data3
    values as CONTROL_CORE_PAD0_DSIPORTA_LANE0X_PAD1_DSIPORTA_LANE0Y.DSIPORTA_LANE{i}Y_PULLUDENABLE
  [2:0] RFBI_DATA3_MUXMODE rw — Functional multiplexing selection for pad rfbi_data3
    0=SEL_RFBI_DATA3 (Select rfbi_data3); 6=SEL_GPIO6_169 (Select gpio6_169); 3=SEL_DISPC_DATA3 (Select dispc_data3); 4=SEL_JTAGTAPEXT_NTRST (Select jtagtapext_ntrst); 7=SEL_SAFE_MODE_CORE93 (Select safe_mode_core93); 5=SEL_DRM_EMU7 (Select drm_emu7)
0x120 CONTROL_CORE_PAD0_RFBI_DATA1_PAD1_RFBI_DATA0 — Register control for Pads rfbi_data1 and rfbi_data0 Access conditions. Read: unrestricted, Write: unrestricted
  [31] RFBI_DATA0_WAKEUPEVENT ro — Pad_x wake-up event status latched in the IO
    values as CONTROL_CORE_PAD0_DSIPORTC_TE0_PAD1_TIMER9_PWM_EVT.TIMER9_PWM_EVT_WAKEUPEVENT
  [30] RFBI_DATA0_WAKEUPENABLE rw — Input pad wake-up enable
    values as CONTROL_CORE_PAD0_DSIPORTC_TE0_PAD1_TIMER9_PWM_EVT.TIMER9_PWM_EVT_WAKEUPENABLE
  [24] RFBI_DATA0_INPUTENABLE rw — Input enable value for pad rfbi_data0
    values as CONTROL_CORE_PAD0_DSIPORTA_LANE0X_PAD1_DSIPORTA_LANE0Y.DSIPORTA_LANE{i}Y_INPUTENABLE
  [21] RFBI_DATA0_PWRDOWN rw — Power Down setting for pad rfbi_data0
    values as CONTROL_CORE_PAD0_DSIPORTA_LANE0X_PAD1_DSIPORTA_LANE0Y.DSIPORTA_LANE{i}Y_PWRDOWN
  [20] RFBI_DATA0_PULLTYPESELECT rw — Pull-Up/Down selection for pad rfbi_data0
    0=Pull-Down selected; 1=Pull-Up selected
  [19] RFBI_DATA0_PULLUDENABLE rw — Pull-Up/Down enable for pad rfbi_data0
    values as CONTROL_CORE_PAD0_DSIPORTA_LANE0X_PAD1_DSIPORTA_LANE0Y.DSIPORTA_LANE{i}Y_PULLUDENABLE
  [18:16] RFBI_DATA0_MUXMODE rw — Functional multiplexing selection for pad rfbi_data0
    0=SEL_RFBI_DATA0 (Select rfbi_data0); 6=SEL_GPIO6_166 (Select gpio6_166); 3=SEL_DISPC_DATA0 (Select dispc_data0); 4=SEL_JTAGTAPEXT_RTCK (Select jtagtapext_rtck); 7=SEL_SAFE_MODE_CORE90 (Select safe_mode_core90); 5=SEL_DRM_EMU4 (Select drm_emu4)
  [15] RFBI_DATA1_WAKEUPEVENT ro — Pad_x wake-up event status latched in the IO
    values as CONTROL_CORE_PAD0_DSIPORTC_TE0_PAD1_TIMER9_PWM_EVT.TIMER9_PWM_EVT_WAKEUPEVENT
  [14] RFBI_DATA1_WAKEUPENABLE rw — Input pad wake-up enable
    values as CONTROL_CORE_PAD0_DSIPORTC_TE0_PAD1_TIMER9_PWM_EVT.TIMER9_PWM_EVT_WAKEUPENABLE
  [8] RFBI_DATA1_INPUTENABLE rw — Input enable value for pad rfbi_data1
    values as CONTROL_CORE_PAD0_DSIPORTA_LANE0X_PAD1_DSIPORTA_LANE0Y.DSIPORTA_LANE{i}Y_INPUTENABLE
  [5] RFBI_DATA1_PWRDOWN rw — Power Down setting for pad rfbi_data1
    values as CONTROL_CORE_PAD0_DSIPORTA_LANE0X_PAD1_DSIPORTA_LANE0Y.DSIPORTA_LANE{i}Y_PWRDOWN
  [4] RFBI_DATA1_PULLTYPESELECT rw — Pull-Up/Down selection for pad rfbi_data1
    0=Pull-Down selected; 1=Pull-Up selected
  [3] RFBI_DATA1_PULLUDENABLE rw — Pull-Up/Down enable for pad rfbi_data1
    values as CONTROL_CORE_PAD0_DSIPORTA_LANE0X_PAD1_DSIPORTA_LANE0Y.DSIPORTA_LANE{i}Y_PULLUDENABLE
  [2:0] RFBI_DATA1_MUXMODE rw — Functional multiplexing selection for pad rfbi_data1
    6=SEL_GPIO6_167 (Select gpio6_167); 7=SEL_SAFE_MODE_CORE91 (Select safe_mode_core91); 0=SEL_RFBI_DATA1 (Select rfbi_data1); 4=SEL_UART3_RX_IRRX (Select uart3_rx_irrx); 5=SEL_DRM_EMU5 (Select drm_emu5); 3=SEL_DISPC_DATA1 (Select dispc_data1)
0x124 CONTROL_CORE_PAD0_RFBI_WE_PAD1_RFBI_CS0 — Register control for Pads rfbi_we and rfbi_cs0 Access conditions. Read: unrestricted, Write: unrestricted
  [31] RFBI_CS0_WAKEUPEVENT ro — Pad_x wake-up event status latched in the IO
    values as CONTROL_CORE_PAD0_DSIPORTC_TE0_PAD1_TIMER9_PWM_EVT.TIMER9_PWM_EVT_WAKEUPEVENT
  [30] RFBI_CS0_WAKEUPENABLE rw — Input pad wake-up enable
    values as CONTROL_CORE_PAD0_DSIPORTC_TE0_PAD1_TIMER9_PWM_EVT.TIMER9_PWM_EVT_WAKEUPENABLE
  [24] RFBI_CS0_INPUTENABLE rw — Input enable value for pad rfbi_cs0
    values as CONTROL_CORE_PAD0_DSIPORTA_LANE0X_PAD1_DSIPORTA_LANE0Y.DSIPORTA_LANE{i}Y_INPUTENABLE
  [21] RFBI_CS0_PWRDOWN rw — Power Down setting for pad rfbi_cs0
    values as CONTROL_CORE_PAD0_DSIPORTA_LANE0X_PAD1_DSIPORTA_LANE0Y.DSIPORTA_LANE{i}Y_PWRDOWN
  [20] RFBI_CS0_PULLTYPESELECT rw — Pull-Up/Down selection for pad rfbi_cs0
    0=Pull-Down selected; 1=Pull-Up selected
  [19] RFBI_CS0_PULLUDENABLE rw — Pull-Up/Down enable for pad rfbi_cs0
    values as CONTROL_CORE_PAD0_DSIPORTA_LANE0X_PAD1_DSIPORTA_LANE0Y.DSIPORTA_LANE{i}Y_PULLUDENABLE
  [18:16] RFBI_CS0_MUXMODE rw — Functional multiplexing selection for pad rfbi_cs0
    0=SEL_RFBI_CS0 (Select rfbi_cs0); 6=SEL_GPIO6_163 (Select gpio6_163); 3=SEL_DISPC_HSYNC (Select dispc_hsync); 7=SEL_SAFE_MODE_CORE98 (Select safe_mode_core98); 5=SEL_DRM_EMU3 (Select drm_emu3)
  [15] RFBI_WE_WAKEUPEVENT ro — Pad_x wake-up event status latched in the IO
    values as CONTROL_CORE_PAD0_DSIPORTC_TE0_PAD1_TIMER9_PWM_EVT.TIMER9_PWM_EVT_WAKEUPEVENT
  [14] RFBI_WE_WAKEUPENABLE rw — Input pad wake-up enable
    values as CONTROL_CORE_PAD0_DSIPORTC_TE0_PAD1_TIMER9_PWM_EVT.TIMER9_PWM_EVT_WAKEUPENABLE
  [8] RFBI_WE_INPUTENABLE rw — Input enable value for pad rfbi_we
    values as CONTROL_CORE_PAD0_DSIPORTA_LANE0X_PAD1_DSIPORTA_LANE0Y.DSIPORTA_LANE{i}Y_INPUTENABLE
  [5] RFBI_WE_PWRDOWN rw — Power Down setting for pad rfbi_we
    values as CONTROL_CORE_PAD0_DSIPORTA_LANE0X_PAD1_DSIPORTA_LANE0Y.DSIPORTA_LANE{i}Y_PWRDOWN
  [4] RFBI_WE_PULLTYPESELECT rw — Pull-Up/Down selection for pad rfbi_we
    0=Pull-Down selected; 1=Pull-Up selected
  [3] RFBI_WE_PULLUDENABLE rw — Pull-Up/Down enable for pad rfbi_we
    values as CONTROL_CORE_PAD0_DSIPORTA_LANE0X_PAD1_DSIPORTA_LANE0Y.DSIPORTA_LANE{i}Y_PULLUDENABLE
  [2:0] RFBI_WE_MUXMODE rw — Functional multiplexing selection for pad rfbi_we
    0=SEL_RFBI_WE (Select rfbi_we); 6=SEL_GPIO6_162 (Select gpio6_162); 3=SEL_DISPC_VSYNC (Select dispc_vsync); 7=SEL_SAFE_MODE_CORE99 (Select safe_mode_core99); 5=SEL_DRM_EMU2 (Select drm_emu2)
0x128 CONTROL_CORE_PAD0_RFBI_A0_PAD1_RFBI_RE — Register control for Pads rfbi_a0 and rfbi_re Access conditions. Read: unrestricted, Write: unrestricted
  [31] RFBI_RE_WAKEUPEVENT ro — Pad_x wake-up event status latched in the IO
    values as CONTROL_CORE_PAD0_DSIPORTC_TE0_PAD1_TIMER9_PWM_EVT.TIMER9_PWM_EVT_WAKEUPEVENT
  [30] RFBI_RE_WAKEUPENABLE rw — Input pad wake-up enable
    values as CONTROL_CORE_PAD0_DSIPORTC_TE0_PAD1_TIMER9_PWM_EVT.TIMER9_PWM_EVT_WAKEUPENABLE
  [24] RFBI_RE_INPUTENABLE rw — Input enable value for pad rfbi_re
    values as CONTROL_CORE_PAD0_DSIPORTA_LANE0X_PAD1_DSIPORTA_LANE0Y.DSIPORTA_LANE{i}Y_INPUTENABLE
  [21] RFBI_RE_PWRDOWN rw — Power Down setting for pad rfbi_re
    values as CONTROL_CORE_PAD0_DSIPORTA_LANE0X_PAD1_DSIPORTA_LANE0Y.DSIPORTA_LANE{i}Y_PWRDOWN
  [20] RFBI_RE_PULLTYPESELECT rw — Pull-Up/Down selection for pad rfbi_re
    0=Pull-Down selected; 1=Pull-Up selected
  [19] RFBI_RE_PULLUDENABLE rw — Pull-Up/Down enable for pad rfbi_re
    values as CONTROL_CORE_PAD0_DSIPORTA_LANE0X_PAD1_DSIPORTA_LANE0Y.DSIPORTA_LANE{i}Y_PULLUDENABLE
  [18:16] RFBI_RE_MUXMODE rw — Functional multiplexing selection for pad rfbi_re
    0=SEL_RFBI_RE (Select rfbi_re); 3=SEL_DISPC_PCLK (Select dispc_pclk); 7=SEL_SAFE_MODE_CORE74 (Select safe_mode_core74); 4=SEL_KBD_COL4 (Select kbd_col4); 6=SEL_GPIO6_164 (Select gpio6_164)
  [15] RFBI_A0_WAKEUPEVENT ro — Pad_x wake-up event status latched in the IO
    values as CONTROL_CORE_PAD0_DSIPORTC_TE0_PAD1_TIMER9_PWM_EVT.TIMER9_PWM_EVT_WAKEUPEVENT
  [14] RFBI_A0_WAKEUPENABLE rw — Input pad wake-up enable
    values as CONTROL_CORE_PAD0_DSIPORTC_TE0_PAD1_TIMER9_PWM_EVT.TIMER9_PWM_EVT_WAKEUPENABLE
  [8] RFBI_A0_INPUTENABLE rw — Input enable value for pad rfbi_a0
    values as CONTROL_CORE_PAD0_DSIPORTA_LANE0X_PAD1_DSIPORTA_LANE0Y.DSIPORTA_LANE{i}Y_INPUTENABLE
  [5] RFBI_A0_PWRDOWN rw — Power Down setting for pad rfbi_a0
    values as CONTROL_CORE_PAD0_DSIPORTA_LANE0X_PAD1_DSIPORTA_LANE0Y.DSIPORTA_LANE{i}Y_PWRDOWN
  [4] RFBI_A0_PULLTYPESELECT rw — Pull-Up/Down selection for pad rfbi_a0
    0=Pull-Down selected; 1=Pull-Up selected
  [3] RFBI_A0_PULLUDENABLE rw — Pull-Up/Down enable for pad rfbi_a0
    values as CONTROL_CORE_PAD0_DSIPORTA_LANE0X_PAD1_DSIPORTA_LANE0Y.DSIPORTA_LANE{i}Y_PULLUDENABLE
  [2:0] RFBI_A0_MUXMODE rw — Functional multiplexing selection for pad rfbi_a0
    0=SEL_RFBI_A0 (Select rfbi_a0); 3=SEL_DISPC_DE (Select dispc_de); 7=SEL_SAFE_MODE_CORE75 (Select safe_mode_core75); 4=SEL_KBD_ROW4 (Select kbd_row4); 6=SEL_GPIO6_165 (Select gpio6_165)
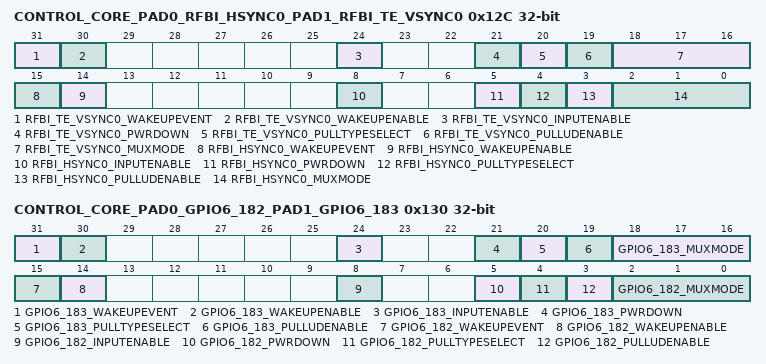
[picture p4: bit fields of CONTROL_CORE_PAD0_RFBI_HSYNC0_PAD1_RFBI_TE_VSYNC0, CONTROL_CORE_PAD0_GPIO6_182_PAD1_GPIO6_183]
0x12C CONTROL_CORE_PAD0_RFBI_HSYNC0_PAD1_RFBI_TE_VSYNC0 — Register control for Pads rfbi_hsync0 and rfbi_te_vsync0 Access conditions. Read: unrestricted, Write: unrestricted
  [31] RFBI_TE_VSYNC0_WAKEUPEVENT ro — Pad_x wake-up event status latched in the IO
    values as CONTROL_CORE_PAD0_DSIPORTC_TE0_PAD1_TIMER9_PWM_EVT.TIMER9_PWM_EVT_WAKEUPEVENT
  [30] RFBI_TE_VSYNC0_WAKEUPENABLE rw — Input pad wake-up enable
    values as CONTROL_CORE_PAD0_DSIPORTC_TE0_PAD1_TIMER9_PWM_EVT.TIMER9_PWM_EVT_WAKEUPENABLE
  [24] RFBI_TE_VSYNC0_INPUTENABLE rw — Input enable value for pad rfbi_te_vsync0
    values as CONTROL_CORE_PAD0_DSIPORTA_LANE0X_PAD1_DSIPORTA_LANE0Y.DSIPORTA_LANE{i}Y_INPUTENABLE
  [21] RFBI_TE_VSYNC0_PWRDOWN rw — Power Down setting for pad rfbi_te_vsync0
    values as CONTROL_CORE_PAD0_DSIPORTA_LANE0X_PAD1_DSIPORTA_LANE0Y.DSIPORTA_LANE{i}Y_PWRDOWN
  [20] RFBI_TE_VSYNC0_PULLTYPESELECT rw — Pull-Up/Down selection for pad rfbi_te_vsync0
    0=Pull-Down selected; 1=Pull-Up selected
  [19] RFBI_TE_VSYNC0_PULLUDENABLE rw — Pull-Up/Down enable for pad rfbi_te_vsync0
    values as CONTROL_CORE_PAD0_DSIPORTA_LANE0X_PAD1_DSIPORTA_LANE0Y.DSIPORTA_LANE{i}Y_PULLUDENABLE
  [18:16] RFBI_TE_VSYNC0_MUXMODE rw — Functional multiplexing selection for pad rfbi_te_vsync0
    6=SEL_GPIO6_161 (Select gpio6_161); 7=SEL_SAFE_MODE_CORE73 (Select safe_mode_core73); 0=SEL_RFBI_TE_VSYNC0 (Select rfbi_te_vsync0); 4=SEL_KBD_ROW5 (Select kbd_row5); 5=SEL_JTAG_SEL (Select jtag_sel); 3=SEL_DISPC_DATA16 (Select dispc_data16)
  [15] RFBI_HSYNC0_WAKEUPEVENT ro — Pad_x wake-up event status latched in the IO
    values as CONTROL_CORE_PAD0_DSIPORTC_TE0_PAD1_TIMER9_PWM_EVT.TIMER9_PWM_EVT_WAKEUPEVENT
  [14] RFBI_HSYNC0_WAKEUPENABLE rw — Input pad wake-up enable
    values as CONTROL_CORE_PAD0_DSIPORTC_TE0_PAD1_TIMER9_PWM_EVT.TIMER9_PWM_EVT_WAKEUPENABLE
  [8] RFBI_HSYNC0_INPUTENABLE rw — Input enable value for pad rfbi_hsync0
    values as CONTROL_CORE_PAD0_DSIPORTA_LANE0X_PAD1_DSIPORTA_LANE0Y.DSIPORTA_LANE{i}Y_INPUTENABLE
  [5] RFBI_HSYNC0_PWRDOWN rw — Power Down setting for pad rfbi_hsync0
    values as CONTROL_CORE_PAD0_DSIPORTA_LANE0X_PAD1_DSIPORTA_LANE0Y.DSIPORTA_LANE{i}Y_PWRDOWN
  [4] RFBI_HSYNC0_PULLTYPESELECT rw — Pull-Up/Down selection for pad rfbi_hsync0
    0=Pull-Down selected; 1=Pull-Up selected
  [3] RFBI_HSYNC0_PULLUDENABLE rw — Pull-Up/Down enable for pad rfbi_hsync0
    values as CONTROL_CORE_PAD0_DSIPORTA_LANE0X_PAD1_DSIPORTA_LANE0Y.DSIPORTA_LANE{i}Y_PULLUDENABLE
  [2:0] RFBI_HSYNC0_MUXMODE rw — Functional multiplexing selection for pad rfbi_hsync0
    0=SEL_RFBI_HSYNC0 (Select rfbi_hsync0); 3=SEL_DISPC_DATA17 (Select dispc_data17); 7=SEL_SAFE_MODE_CORE72 (Select safe_mode_core72); 4=SEL_KBD_COL5 (Select kbd_col5); 6=SEL_GPIO6_160 (Select gpio6_160)
0x130 CONTROL_CORE_PAD0_GPIO6_182_PAD1_GPIO6_183 — Register control for Pads gpio6_182 and gpio6_183 Access conditions. Read: unrestricted, Write: unrestricted
  [31] GPIO6_183_WAKEUPEVENT ro — Pad_x wake-up event status latched in the IO
    values as CONTROL_CORE_PAD0_DSIPORTC_TE0_PAD1_TIMER9_PWM_EVT.TIMER9_PWM_EVT_WAKEUPEVENT
  [30] GPIO6_183_WAKEUPENABLE rw — Input pad wake-up enable
    values as CONTROL_CORE_PAD0_DSIPORTC_TE0_PAD1_TIMER9_PWM_EVT.TIMER9_PWM_EVT_WAKEUPENABLE
  [24] GPIO6_183_INPUTENABLE rw — Input enable value for pad gpio6_183
    values as CONTROL_CORE_PAD0_DSIPORTA_LANE0X_PAD1_DSIPORTA_LANE0Y.DSIPORTA_LANE{i}Y_INPUTENABLE
  [21] GPIO6_183_PWRDOWN rw — Power Down setting for pad gpio6_183
    values as CONTROL_CORE_PAD0_DSIPORTA_LANE0X_PAD1_DSIPORTA_LANE0Y.DSIPORTA_LANE{i}Y_PWRDOWN
  [20] GPIO6_183_PULLTYPESELECT rw — Pull-Up/Down selection for pad gpio6_183
    0=Pull-Down selected; 1=Pull-Up selected
  [19] GPIO6_183_PULLUDENABLE rw — Pull-Up/Down enable for pad gpio6_183
    values as CONTROL_CORE_PAD0_DSIPORTA_LANE0X_PAD1_DSIPORTA_LANE0Y.DSIPORTA_LANE{i}Y_PULLUDENABLE
  [18:16] GPIO6_183_MUXMODE rw — Functional multiplexing selection for pad gpio6_183
    0=SEL_GPIO6_183 (Select gpio6_183); 3=SEL_DISPC_DATA19 (Select dispc_data19); 7=SEL_SAFE_MODE_CORE85 (Select safe_mode_core85); 4=SEL_KBD_COL1 (Select kbd_col1); 6=SEL_GPIO6_183_1 (Select gpio6_183)
  [15] GPIO6_182_WAKEUPEVENT ro — Pad_x wake-up event status latched in the IO
    values as CONTROL_CORE_PAD0_DSIPORTC_TE0_PAD1_TIMER9_PWM_EVT.TIMER9_PWM_EVT_WAKEUPEVENT
  [14] GPIO6_182_WAKEUPENABLE rw — Input pad wake-up enable
    values as CONTROL_CORE_PAD0_DSIPORTC_TE0_PAD1_TIMER9_PWM_EVT.TIMER9_PWM_EVT_WAKEUPENABLE
  [8] GPIO6_182_INPUTENABLE rw — Input enable value for pad gpio6_182
    values as CONTROL_CORE_PAD0_DSIPORTA_LANE0X_PAD1_DSIPORTA_LANE0Y.DSIPORTA_LANE{i}Y_INPUTENABLE
  [5] GPIO6_182_PWRDOWN rw — Power Down setting for pad gpio6_182
    values as CONTROL_CORE_PAD0_DSIPORTA_LANE0X_PAD1_DSIPORTA_LANE0Y.DSIPORTA_LANE{i}Y_PWRDOWN
  [4] GPIO6_182_PULLTYPESELECT rw — Pull-Up/Down selection for pad gpio6_182
    0=Pull-Down selected; 1=Pull-Up selected
  [3] GPIO6_182_PULLUDENABLE rw — Pull-Up/Down enable for pad gpio6_182
    values as CONTROL_CORE_PAD0_DSIPORTA_LANE0X_PAD1_DSIPORTA_LANE0Y.DSIPORTA_LANE{i}Y_PULLUDENABLE
  [2:0] GPIO6_182_MUXMODE rw — Functional multiplexing selection for pad gpio6_182
    0=SEL_GPIO6_182 (Select gpio6_182); 3=SEL_DISPC_DATA18 (Select dispc_data18); 7=SEL_SAFE_MODE_CORE84 (Select safe_mode_core84); 4=SEL_KBD_COL0 (Select kbd_col0); 6=SEL_GPIO6_182_1 (Select gpio6_182)
